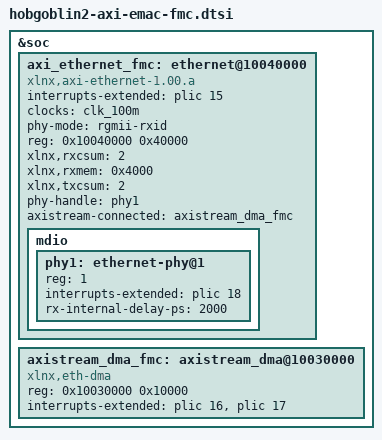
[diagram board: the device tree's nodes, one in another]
// SPDX-License-Identifier: (GPL-2.0 OR MIT)
/*
 * Copyright (c) 2025 Codasip GmbH
 *
 * Hobgoblin FPGA platform, AXI ethernet description. This is a gigabit
 * capable Ethernet controller that does DMA and TCP checksum offload.
 *
 * This is usually the second Ethernet controller in the system. Usually added
 * in via the FMC-Lite extension board. This has a MicroSemi VSC8541 phy on
 * board. For the VCU118 board at least a 2ns delay has to be inserted on the
 * RX side, hence the use of the rxid rgmii type.
 */

&soc {
	axi_ethernet_fmc: ethernet@10040000 {
		compatible = "xlnx,axi-ethernet-1.00.a";
		interrupts-extended = <&plic 15>;
		clock-names = "s_axi_lite_clk";
		clocks = <&clk_100m>;
		phy-mode = "rgmii-rxid";
		reg = <0x10040000 0x40000>;
		xlnx,rxcsum = <2>;
		xlnx,rxmem = <0x4000>;
		xlnx,txcsum = <2>;
		phy-handle = <&phy1>;
		axistream-connected = <&axistream_dma_fmc>;

		mdio {
			#address-cells = <1>;
			#size-cells = <0>;
			phy1: ethernet-phy@1 {
				device_type = "ethernet-phy";
				reg = <1>;
				interrupts-extended = <&plic 18>;
				rx-internal-delay-ps = <2000>;
			};
		};
	};
	/* U-boot does not support specifying the DMA directly in the
	 * axi_ethernet above. The kernel does support it though
	 */
	axistream_dma_fmc: axistream_dma@10030000  {
		compatible = "xlnx,eth-dma";
		reg = <0x10030000 0x10000>;
		interrupts-extended = <&plic 16>, <&plic 17>;
	};
};
